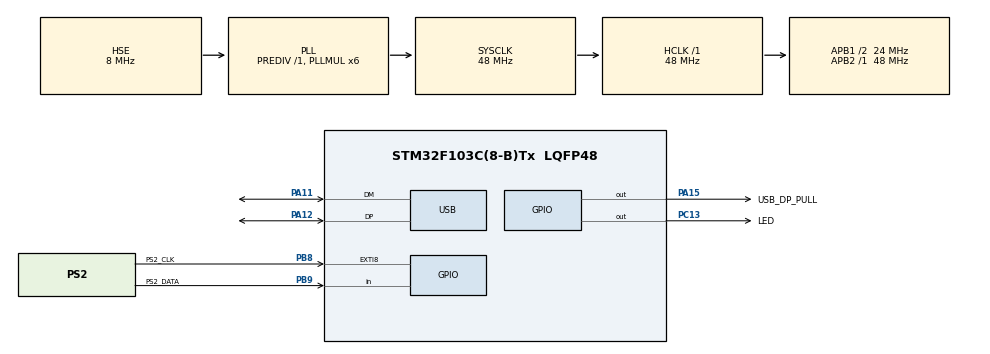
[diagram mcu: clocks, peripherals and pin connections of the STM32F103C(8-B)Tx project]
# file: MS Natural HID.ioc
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Mcu.Family=STM32F1
Mcu.Name=STM32F103C(8-B)Tx
Mcu.Package=LQFP48
NVIC.EXTI9_5_IRQn=true\:1\:0\:true\:false\:true\:true\:true
NVIC.PriorityGroup=NVIC_PRIORITYGROUP_4
NVIC.USB_LP_CAN1_RX0_IRQn=true\:0\:0\:false\:false\:true\:false\:true
PA11.Mode=Device
PA11.Signal=USB_DM
PA12.Mode=Device
PA12.Signal=USB_DP
PA13.Mode=Serial_Wire
PA13.Signal=SYS_JTMS-SWDIO
PA14.Mode=Serial_Wire
PA14.Signal=SYS_JTCK-SWCLK
PA15.GPIO_Label=USB_DP_PULL
PA15.Signal=GPIO_Output
PB8.GPIO_Label=PS2_CLK
PB8.GPIO_ModeDefaultEXTI=GPIO_MODE_IT_FALLING
PB8.GPIO_PuPd=GPIO_PULLUP
PB8.Signal=GPXTI8
PB9.GPIO_Label=PS2_DATA
PB9.GPIO_PuPd=GPIO_PULLUP
PB9.Signal=GPIO_Input
PC13-TAMPER-RTC.GPIO_Label=LED
PC13-TAMPER-RTC.Signal=GPIO_Output
PD0-OSC_IN.Mode=HSE-External-Oscillator
PD0-OSC_IN.Signal=RCC_OSC_IN
PD1-OSC_OUT.Mode=HSE-External-Oscillator
PD1-OSC_OUT.Signal=RCC_OSC_OUT
ProjectManager.HeapSize=0x200
ProjectManager.StackSize=0x400
ProjectManager.TargetToolchain=STM32CubeIDE
RCC.AHBFreq_Value=48000000
RCC.APB1CLKDivider=RCC_HCLK_DIV2
RCC.APB1Freq_Value=24000000
RCC.APB1TimFreq_Value=48000000
RCC.APB2Freq_Value=48000000
RCC.APB2TimFreq_Value=48000000
RCC.HCLKFreq_Value=48000000
RCC.PLLMUL=RCC_PLL_MUL6
RCC.PLLSourceVirtual=RCC_PLLSOURCE_HSE
RCC.SYSCLKFreq_VALUE=48000000
RCC.SYSCLKSource=RCC_SYSCLKSOURCE_PLLCLK
RCC.USBFreq_Value=48000000
TIM1.Period=65535
TIM1.Prescaler=48-1
USB_DEVICE.CLASS_NAME_FS=HID
USB_DEVICE.PRODUCT_STRING_HID_FS=MS Natural Keyboard
USB_DEVICE.VirtualMode=Hid
USB_DEVICE.VirtualModeFS=Hid_FS
VP_TIM1_VS_ClockSourceINT.Mode=Internal
VP_USB_DEVICE_VS_USB_DEVICE_HID_FS.Mode=HID_FS
board=custom

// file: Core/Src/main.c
/* USER CODE BEGIN Header */
/**
  ******************************************************************************
  * @file           : main.c
  * @brief          : Main program body
  ******************************************************************************
  * @attention
  *
  * <h2><center>&copy; Copyright (c) 2021 STMicroelectronics.
  * All rights reserved.</center></h2>
  *
  * This software component is licensed by ST under BSD 3-Clause license,
  * the "License"; You may not use this file except in compliance with the
  * License. You may obtain a copy of the License at:
  *                        opensource.org/licenses/BSD-3-Clause
  *
  ******************************************************************************
  */
/* USER CODE END Header */
#include "main.h"
#include "tim.h"
#include "usb_device.h"
#include "gpio.h"

/* USER CODE BEGIN Includes */
#include "usbd_hid.h"
#include "ps2.h"
#include "keyboard.h"

/* USER CODE END Includes */

/* USER CODE BEGIN PTD */
extern USBD_HandleTypeDef hUsbDeviceFS;

/* USER CODE END PTD */

void SystemClock_Config(void);

int main(void)
{

  /* MCU Configuration--------------------------------------------------------*/

  /* Reset of all peripherals, Initializes the Flash interface and the Systick. */
HAL_Init();

  /* Configure the system clock */
  SystemClock_Config();

  /* Initialize all configured peripherals */
  MX_GPIO_Init();
  MX_USB_DEVICE_Init();
  MX_TIM1_Init();
  /* USER CODE BEGIN 2 */
  HAL_TIM_Base_Start(&htim1);
  _delay_ms(250); // USB re-enumeration
  HAL_GPIO_WritePin(USB_DP_PULL_GPIO_Port, USB_DP_PULL_Pin, 1); // enable pull-up
  reset_us_counter();
  init_PS2();

  /* USER CODE END 2 */

  /* Infinite loop */
  /* USER CODE BEGIN WHILE */
  while (1)
  {
	  process_PS2(); // check if new data from keyboard, or LEDs should be updated on keyboard
	  process_keyboard_USB(); // check if we can send data over USB
	  _delay_ms(1);
	  continue;
   /* USER CODE END WHILE */

  }
}

void SystemClock_Config(void)
{
  RCC_OscInitTypeDef RCC_OscInitStruct = {0};
  RCC_ClkInitTypeDef RCC_ClkInitStruct = {0};
  RCC_PeriphCLKInitTypeDef PeriphClkInit = {0};

  /** Initializes the RCC Oscillators according to the specified parameters
  * in the RCC_OscInitTypeDef structure.
  */
  RCC_OscInitStruct.OscillatorType = RCC_OSCILLATORTYPE_HSE;
  RCC_OscInitStruct.HSEState = RCC_HSE_ON;
  RCC_OscInitStruct.HSEPredivValue = RCC_HSE_PREDIV_DIV1;
  RCC_OscInitStruct.HSIState = RCC_HSI_ON;
  RCC_OscInitStruct.PLL.PLLState = RCC_PLL_ON;
  RCC_OscInitStruct.PLL.PLLSource = RCC_PLLSOURCE_HSE;
  RCC_OscInitStruct.PLL.PLLMUL = RCC_PLL_MUL6;
  if (HAL_RCC_OscConfig(&RCC_OscInitStruct) != HAL_OK)
  {
    Error_Handler();
  }
  /** Initializes the CPU, AHB and APB buses clocks
  */
  RCC_ClkInitStruct.ClockType = RCC_CLOCKTYPE_HCLK|RCC_CLOCKTYPE_SYSCLK
                              |RCC_CLOCKTYPE_PCLK1|RCC_CLOCKTYPE_PCLK2;
  RCC_ClkInitStruct.SYSCLKSource = RCC_SYSCLKSOURCE_PLLCLK;
  RCC_ClkInitStruct.AHBCLKDivider = RCC_SYSCLK_DIV1;
  RCC_ClkInitStruct.APB1CLKDivider = RCC_HCLK_DIV2;
  RCC_ClkInitStruct.APB2CLKDivider = RCC_HCLK_DIV1;

  if (HAL_RCC_ClockConfig(&RCC_ClkInitStruct, FLASH_LATENCY_1) != HAL_OK)
  {
    Error_Handler();
  }
  PeriphClkInit.PeriphClockSelection = RCC_PERIPHCLK_USB;
  PeriphClkInit.UsbClockSelection = RCC_USBCLKSOURCE_PLL;
  if (HAL_RCCEx_PeriphCLKConfig(&PeriphClkInit) != HAL_OK)
  {
    Error_Handler();
  }
}

void Error_Handler(void)
{
  __disable_irq();
  while (1)
  {
  }
}

/************************ (C) COPYRIGHT STMicroelectronics *****END OF FILE****/
